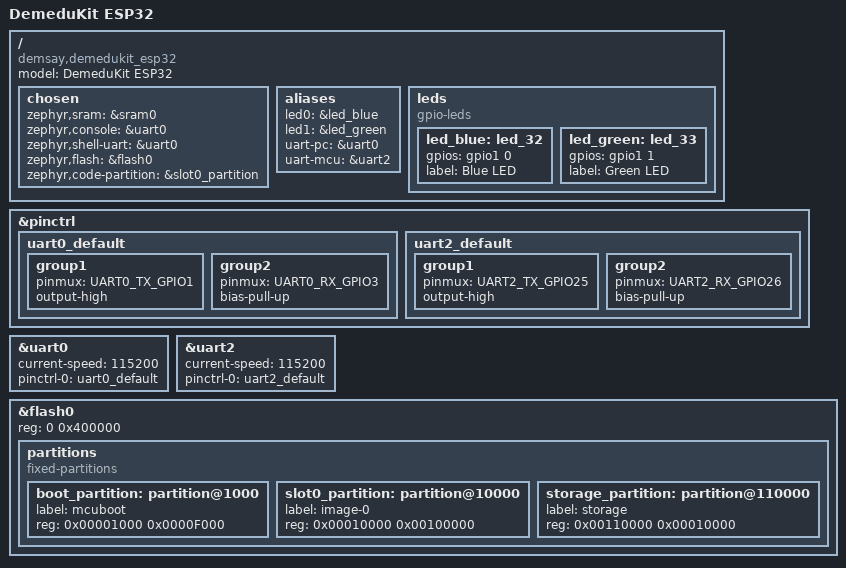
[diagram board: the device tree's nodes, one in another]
/*
 * Copyright (c) 2025 DemeduKit - Consolidated DTS
 * SPDX-License-Identifier: Apache-2.0
 */

/dts-v1/;

#include "demedukit_esp32.dtsi"
#include <zephyr/dt-bindings/pinctrl/esp-pinctrl-common.h>
#include <zephyr/dt-bindings/pinctrl/esp32-pinctrl.h>
#include <zephyr/dt-bindings/pinctrl/esp32-gpio-sigmap.h>
#include <zephyr/dt-bindings/gpio/gpio.h>

/ {
model = "DemeduKit ESP32";
compatible = "demsay,demedukit_esp32";

chosen {
zephyr,sram = &sram0;
zephyr,console = &uart0;
zephyr,shell-uart = &uart0;
zephyr,flash = &flash0;
zephyr,code-partition = &slot0_partition;
};

aliases {
led0 = &led_blue;
led1 = &led_green;
uart-pc = &uart0;
uart-mcu = &uart2;
};

leds {
compatible = "gpio-leds";
led_blue: led_32 {
gpios = <&gpio1 0 GPIO_ACTIVE_HIGH>;
label = "Blue LED";
};
led_green: led_33 {
gpios = <&gpio1 1 GPIO_ACTIVE_HIGH>;
label = "Green LED";
};
};
};

&pinctrl {
uart0_default: uart0_default {
group1 {
pinmux = <UART0_TX_GPIO1>;
output-high;
};
group2 {
pinmux = <UART0_RX_GPIO3>;
bias-pull-up;
};
};

uart2_default: uart2_default {
group1 {
pinmux = <UART2_TX_GPIO25>;
output-high;
};
group2 {
pinmux = <UART2_RX_GPIO26>;
bias-pull-up;
};
};
};

&uart0 {
status = "okay";
current-speed = <115200>;
pinctrl-0 = <&uart0_default>;
pinctrl-names = "default";
};

&uart2 {
status = "okay";
current-speed = <115200>;
pinctrl-0 = <&uart2_default>;
pinctrl-names = "default";
};

&flash0 {
status = "okay";
reg = <0 0x400000>;
partitions {
compatible = "fixed-partitions";
#address-cells = <1>;
#size-cells = <1>;
boot_partition: partition@1000 {
label = "mcuboot";
reg = <0x00001000 0x0000F000>;
};
slot0_partition: partition@10000 {
label = "image-0";
reg = <0x00010000 0x00100000>;
};
storage_partition: partition@110000 {
label = "storage";
reg = <0x00110000 0x00010000>;
};
};
};
